VERSION ""

NS_ :

BS_:

BU_: SENSORBOARD TLB DASHBOARD STEERINGWHEEL DSPACE

BO_ 3221225472 VECTOR__INDEPENDENT_SIG_MSG: 0 Vector__XXX
 SG_ TEMP_7 : 0|16@0+ (0.01,0) [0|80] "°C" Vector__XXX
 SG_ TEMP_6 : 0|16@0+ (0.01,0) [0|80] "°C" Vector__XXX
 SG_ New_Signal_86 : 0|8@1+ (1,0) [0|0] "" Vector__XXX
 SG_ THRESH_CHANGE : 0|1@1+ (1,0) [0|1] "" Vector__XXX
 SG_ FAULT_MSK_EN : 1|1@1+ (1,0) [0|1] "" Vector__XXX
 SG_ FAULT_MSK_DIS : 2|1@1+ (1,0) [0|1] "" Vector__XXX
 SG_ UV_THRESHOLD : 15|16@0+ (1,0) [0|5000] "V" Vector__XXX
 SG_ OV_THRESHOLD : 31|16@0+ (1,0) [0|5000] "V" Vector__XXX
 SG_ TEMP_THRESH : 47|16@0+ (1,0) [0|8000] "°C" Vector__XXX
 SG_ LOW_CELL_V : 7|16@0+ (0.001,0) [0|5] "V" Vector__XXX
 SG_ HIGH_CELL_V : 23|16@0+ (0.001,0) [0|5] "V" Vector__XXX
 SG_ BATT_VOLTAGE : 39|16@0+ (0.001,0) [0|30] "V" Vector__XXX
 SG_ CURRENT : 55|16@0- (1,0) [0|100] "A" Vector__XXX
 SG_ TEMP_4 : 7|16@0+ (0.01,0) [0|80] "°C" Vector__XXX
 SG_ TEMP_5 : 23|16@0+ (0.01,0) [0|80] "°C" Vector__XXX
 SG_ TEMP_0 : 7|16@0+ (0.01,0) [0|80] "°C" Vector__XXX
 SG_ TEMP_1 : 23|16@0+ (0.01,0) [0|80] "°C" Vector__XXX
 SG_ TEMP_2 : 39|16@0+ (0.01,0) [0|80] "°C" Vector__XXX
 SG_ TEMP_3 : 55|16@0+ (0.01,0) [0|80] "°C" Vector__XXX
 SG_ UV_THRESH_ACK : 15|16@0+ (1,0) [0|0] "" Vector__XXX
 SG_ OV_THRESH_ACK : 31|16@0+ (1,0) [0|0] "" Vector__XXX
 SG_ TEMP_THRESH_ACK : 47|16@0+ (1,0) [0|0] "" Vector__XXX
 SG_ MSK_ACK : 63|8@0+ (1,0) [0|0] "" Vector__XXX
 SG_ FLAG_Voltege : 7|32@0- (1,0) [0|0] ""  DSPACE
 SG_ FLAG_Current : 39|32@0- (1,0) [0|0] ""  DSPACE
 SG_ Temp_IGBT_RL : 48|16@1- (1,0) [0|0] "" Vector__XXX
 SG_ Error_Info_RL : 32|16@1- (1,0) [0|0] "" Vector__XXX
 SG_ Temp_Inverter_RL : 16|16@1- (1,0) [0|0] "" Vector__XXX
 SG_ Temp_Motor_RL : 0|16@1- (1,0) [0|0] "" Vector__XXX
 SG_ Temp_IGBT_RR : 48|16@1- (1,0) [0|0] "" Vector__XXX
 SG_ Error_Info_RR : 32|16@1- (1,0) [0|0] "" Vector__XXX
 SG_ Temp_Inverter_RR : 16|16@1- (1,0) [0|0] "" Vector__XXX
 SG_ Temp_Motor_RR : 0|16@1- (1,0) [0|0] "" Vector__XXX
 SG_ Temp_IGBT_FR : 48|16@1- (1,0) [0|0] "" Vector__XXX
 SG_ Error_Info_FR : 32|16@1- (1,0) [0|0] "" Vector__XXX
 SG_ Temp_Inverter_FR : 16|16@1- (1,0) [0|0] "" Vector__XXX
 SG_ Temp_Motor_FR : 0|16@1- (1,0) [0|0] "" Vector__XXX
 SG_ Temp_IGBT_FL : 48|16@1- (1,0) [0|0] "" Vector__XXX
 SG_ Error_Info_FL : 32|16@1+ (1,0) [0|0] "" Vector__XXX
 SG_ Temp_Inverter_FL : 16|16@1- (1,0) [0|0] "" Vector__XXX
 SG_ Temp_Motor_FL : 0|16@1- (1,0) [0|0] "" Vector__XXX
 SG_ Actual_Velocity_RR : 48|16@1- (1,0) [0|0] "" Vector__XXX
 SG_ Actual_Velocity_RL : 32|16@1- (1,0) [0|0] "" Vector__XXX
 SG_ Actual_Velocity_FR : 16|16@1- (1,0) [0|0] "" Vector__XXX
 SG_ Actual_Velocity_FL : 0|16@1- (1,0) [0|0] "" Vector__XXX
 SG_ Throttle : 48|16@1- (1,0) [0|0] "" Vector__XXX
 SG_ ax_est : 32|16@1- (1,0) [0|0] "" Vector__XXX
 SG_ Hydr_Brk_Rep : 16|16@1- (1,0) [0|0] "" Vector__XXX
 SG_ V_CG : 0|16@1- (1,0) [0|0] "" Vector__XXX
 SG_ Power_integral : 32|32@1- (0.01,0) [0|0] ""  DSPACE
 SG_ Electric_power : 0|32@1- (0.01,0) [0|0] ""  DSPACE
 SG_ Yaw_Moment : 0|16@1- (1,0) [0|0] ""  DSPACE
 SG_ Yaw_Reference : 16|16@1- (1,0) [0|0] ""  DSPACE
 SG_ Mag_Current_RR : 48|16@1- (1,0) [0|0] "" Vector__XXX
 SG_ Mag_Current_RL : 32|16@1- (1,0) [0|0] "" Vector__XXX
 SG_ Mag_Current_FR : 16|16@1- (1,0) [0|0] "" Vector__XXX
 SG_ Mag_Current_FL : 0|16@1- (1,0) [0|0] "" Vector__XXX
 SG_ Torque_Feedback_RR : 48|16@1- (1,0) [0|0] "" Vector__XXX
 SG_ Torque_Feedback_RL : 32|16@1- (1,0) [0|0] "" Vector__XXX
 SG_ Torque_Feedback_FR : 16|16@1- (1,0) [0|0] "" Vector__XXX
 SG_ Torque_Feedback_FL : 0|16@1- (1,0) [0|0] "" Vector__XXX
 SG_ AccZ : 32|16@1+ (0.00012742,-4.1768) [-4.1768|4.1736697] ""  DSPACE
 SG_ AccY : 32|16@1+ (0.00012742,-4.1768) [-4.1768|4.1736697] ""  DSPACE
 SG_ PitchRate : 0|16@1+ (0.005,-163.84) [-163.84|163.835] ""  DSPACE
 SG_ AccX : 32|16@1+ (0.00012742,-4.1768) [-4.1768|4.1736697] "g"  DSPACE
 SG_ YawRate : 0|16@1+ (0.005,-163.84) [-163.84|163.835] "deg/s"  DSPACE
 SG_ STEERINGWHEEL_ON_ACK : 0|8@1+ (1,0) [0|0] "" Vector__XXX
 SG_ MAPVALUE_ACK : 8|8@1+ (1,0) [0|0] "" Vector__XXX
 SG_ COCKPIT_GREEN : 0|1@1+ (1,0) [0|1] ""  DASHBOARD
 SG_ BMS_ERR : 1|1@1+ (1,0) [0|1] ""  DASHBOARD
 SG_ IMD_ERR : 2|1@1+ (1,0) [0|1] ""  DASHBOARD
 SG_ BSPD_ERR : 3|1@1+ (1,0) [0|1] ""  DASHBOARD
 SG_ ADC0 : 7|16@0+ (1,0) [0|4095] "LSB"  DSPACE
 SG_ ADC1 : 23|16@0+ (1,0) [0|4095] "LSB"  DSPACE
 SG_ ADC2 : 39|16@0+ (1,0) [0|4095] "LSB"  DSPACE
 SG_ BrakePressureRear : 55|16@0+ (0.027,-9.5) [-9.5|1759.945] "bar"  DSPACE
 SG_ ADC4 : 7|16@0+ (1,0) [0|4095] "LSB"  DSPACE
 SG_ ADC5 : 23|16@0+ (1,0) [0|4095] "LSB"  DSPACE
 SG_ ADC6 : 39|16@0+ (1,0) [0|4095] "LSB"  DSPACE
 SG_ ADC7 : 55|16@0+ (1,0) [0|4095] ""  DSPACE
 SG_ TLB_ON_ACK : 7|8@0+ (1,0) [0|0] ""  DSPACE

BO_ 64 DSPACE_ACK_RTD: 1 DSPACE
 SG_ ACK : 0|8@1+ (1,0) [1|2] ""  DASHBOARD

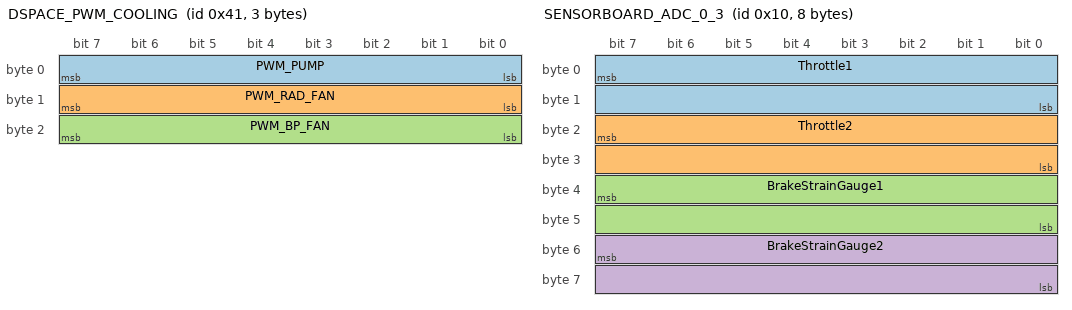
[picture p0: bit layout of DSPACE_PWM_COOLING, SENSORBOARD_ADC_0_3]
BO_ 65 DSPACE_PWM_COOLING: 3 DSPACE
 SG_ PWM_PUMP : 7|8@0+ (1,0) [0|100] "PWM"  DASHBOARD
 SG_ PWM_RAD_FAN : 15|8@0+ (1,0) [0|100] "PWM"  DASHBOARD
 SG_ PWM_BP_FAN : 23|8@0+ (1,0) [0|100] "PWM"  DASHBOARD

BO_ 66 DASH_CMD_RTD: 1 DASHBOARD
 SG_ Dash_button : 0|8@1+ (1,0) [1|2] ""  DSPACE

BO_ 16 SENSORBOARD_ADC_0_3: 8 SENSORBOARD
 SG_ Throttle1 : 7|16@0+ (0.1428,-128.6628) [-128.6628|9229.7352] "%"  DSPACE
 SG_ Throttle2 : 23|16@0+ (-0.1428,447) [0|4095] "%"  DSPACE
 SG_ BrakeStrainGauge1 : 39|16@0+ (-0.0033,0) [-100|1736.44] "%"  DSPACE
 SG_ BrakeStrainGauge2 : 55|16@0+ (-0.0033,0) [-100|1736.445] "%"  DSPACE

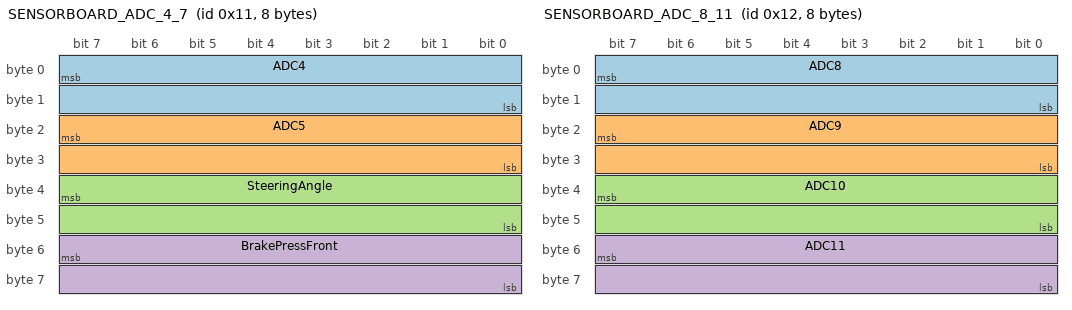
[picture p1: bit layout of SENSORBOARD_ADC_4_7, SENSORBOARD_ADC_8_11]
BO_ 17 SENSORBOARD_ADC_4_7: 8 SENSORBOARD
 SG_ ADC4 : 7|16@0+ (0.0012207,0) [0|4095] "LSB"  DSPACE
 SG_ ADC5 : 23|16@0+ (0.0012207,0) [0|4095] "LSB"  DSPACE
 SG_ SteeringAngle : 39|16@0+ (0.08754,-199) [-199|5537.9339] "deg"  DSPACE
 SG_ BrakePressFront : 55|16@0+ (0.027,-9.5) [-9.5|1759.945] "bar"  DSPACE

BO_ 18 SENSORBOARD_ADC_8_11: 8 SENSORBOARD
 SG_ ADC8 : 7|16@0+ (0.0012207,0) [0|4095] "LSB"  DSPACE
 SG_ ADC9 : 23|16@0+ (0.0012207,0) [0|4095] "LSB"  DSPACE
 SG_ ADC10 : 39|16@0+ (0.0012207,0) [0|4095] "LSB"  DSPACE
 SG_ ADC11 : 55|16@0+ (0.0012207,0) [0|4095] "LSB"  DSPACE

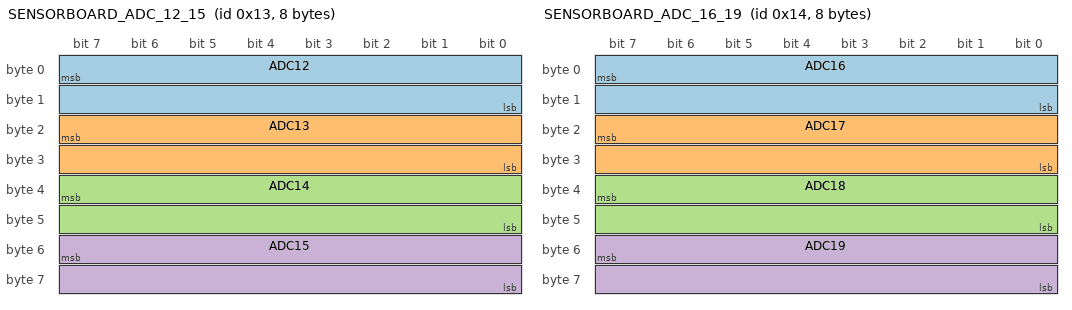
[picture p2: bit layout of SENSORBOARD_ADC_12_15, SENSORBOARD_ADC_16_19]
BO_ 19 SENSORBOARD_ADC_12_15: 8 SENSORBOARD
 SG_ ADC12 : 7|16@0+ (0.0012207,0) [0|4095] "LSB"  DSPACE
 SG_ ADC13 : 23|16@0+ (0.0012207,0) [0|4095] "LSB"  DSPACE
 SG_ ADC14 : 39|16@0+ (0.0012207,0) [0|4095] "LSB"  DSPACE
 SG_ ADC15 : 55|16@0+ (0.0012207,0) [0|4095] "LSB"  DSPACE

BO_ 20 SENSORBOARD_ADC_16_19: 8 SENSORBOARD
 SG_ ADC16 : 7|16@0+ (0.0012207,0) [0|4095] "LSB"  DSPACE
 SG_ ADC17 : 23|16@0+ (0.0012207,0) [0|4095] "LSB"  DSPACE
 SG_ ADC18 : 39|16@0+ (0.0012207,0) [0|4095] "LSB"  DSPACE
 SG_ ADC19 : 55|16@0+ (0.0012207,0) [0|4095] "LSB"  DSPACE

BO_ 1 SENSORBOARD_PING: 1 SENSORBOARD
 SG_ SENSORBOARD_ON_ACK : 7|8@0+ (1,0) [0|0] ""  DSPACE

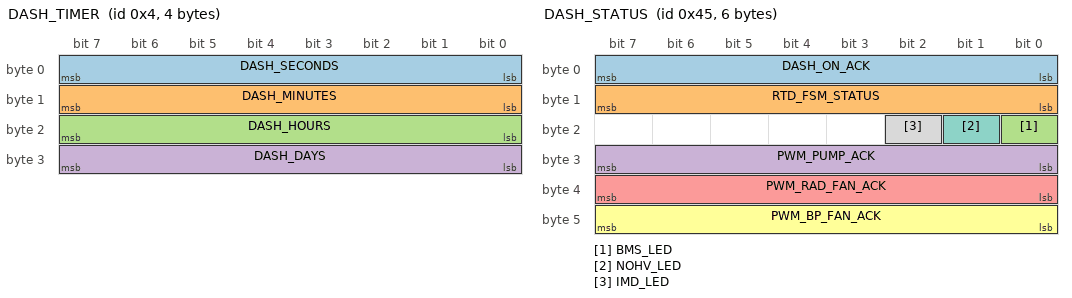
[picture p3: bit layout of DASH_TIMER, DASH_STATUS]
BO_ 4 DASH_TIMER: 4 DASHBOARD
 SG_ DASH_SECONDS : 0|8@1+ (1,0) [0|0] ""  DSPACE
 SG_ DASH_MINUTES : 8|8@1+ (1,0) [0|0] ""  DSPACE
 SG_ DASH_HOURS : 16|8@1+ (1,0) [0|0] ""  DSPACE
 SG_ DASH_DAYS : 24|8@1+ (1,0) [0|0] ""  DSPACE

BO_ 69 DASH_STATUS: 6 DASHBOARD
 SG_ DASH_ON_ACK : 0|8@1+ (1,0) [0|0] ""  DSPACE
 SG_ RTD_FSM_STATUS : 8|8@1+ (1,0) [0|0] ""  DSPACE
 SG_ BMS_LED : 16|1@1+ (1,0) [0|0] ""  DSPACE
 SG_ PWM_PUMP_ACK : 24|8@1+ (1,0) [0|0] ""  DSPACE
 SG_ PWM_RAD_FAN_ACK : 32|8@1+ (1,0) [0|0] ""  DSPACE
 SG_ PWM_BP_FAN_ACK : 40|8@1+ (1,0) [0|0] ""  DSPACE
 SG_ NOHV_LED : 17|1@1+ (1,0) [0|0] ""  DSPACE
 SG_ IMD_LED : 18|1@1+ (1,0) [0|0] ""  DSPACE

BO_ 67 DSPACE_DASH_TIMER: 2 DSPACE
 SG_ CMD_COUNT0 : 0|8@1+ (1,0) [0|0] ""  DASHBOARD
 SG_ CMD_COUNT1 : 8|8@1+ (1,0) [0|0] ""  DASHBOARD

CM_ BO_ 3221225472 "This is a message for not used signals, created by Vector CANdb++ DBC OLE DB Provider.";
CM_ SG_ 3221225472 TEMP_7 "x100";
CM_ SG_ 3221225472 TEMP_6 "x100";
CM_ SG_ 3221225472 UV_THRESHOLD "x1000";
CM_ SG_ 3221225472 OV_THRESHOLD "x1000";
CM_ SG_ 3221225472 TEMP_THRESH "x100";
CM_ SG_ 3221225472 LOW_CELL_V "x1000";
CM_ SG_ 3221225472 HIGH_CELL_V "x1000";
CM_ SG_ 3221225472 BATT_VOLTAGE "x1000";
CM_ SG_ 3221225472 CURRENT "x100";
CM_ SG_ 3221225472 TEMP_4 "x100";
CM_ SG_ 3221225472 TEMP_5 "x100";
CM_ SG_ 3221225472 TEMP_0 "x100";
CM_ SG_ 3221225472 TEMP_1 "x100";
CM_ SG_ 3221225472 TEMP_2 "x100";
CM_ SG_ 3221225472 TEMP_3 "x100";
CM_ SG_ 64 ACK "Feedback of the dash button
1= contactor enable active
2=ready to drive active
3=contactor opened
";
CM_ SG_ 66 Dash_button "
";
CM_ SG_ 67 CMD_COUNT0 "if 0xFF - Read
if 0x46 - Reset";
CM_ SG_ 67 CMD_COUNT1 "if 0xFE - Read
if 0x46 - Reset";
VAL_ 64 ACK 1 "CTOR EN Acknoledge" 2 "RTD Acknowledge" 3 "Contactors opened acknowledge" ;
VAL_ 66 Dash_button 1 "Activate Contactor enable" 2 "Activate Ready to drive" ;
VAL_ 69 RTD_FSM_STATUS 0 "IDLE" 1 "CTOR_EN" 2 "WAIT_CTOR_EN_ACT" 3 "RTD_EN" 4 "WAIT_RTD_EN_ACK" 5 "RTD" 6 "STOP" ;
VAL_ 67 CMD_COUNT0 255 "Read" 70 "Reset" ;
VAL_ 67 CMD_COUNT1 254 "Read" 70 "Reset" ;
